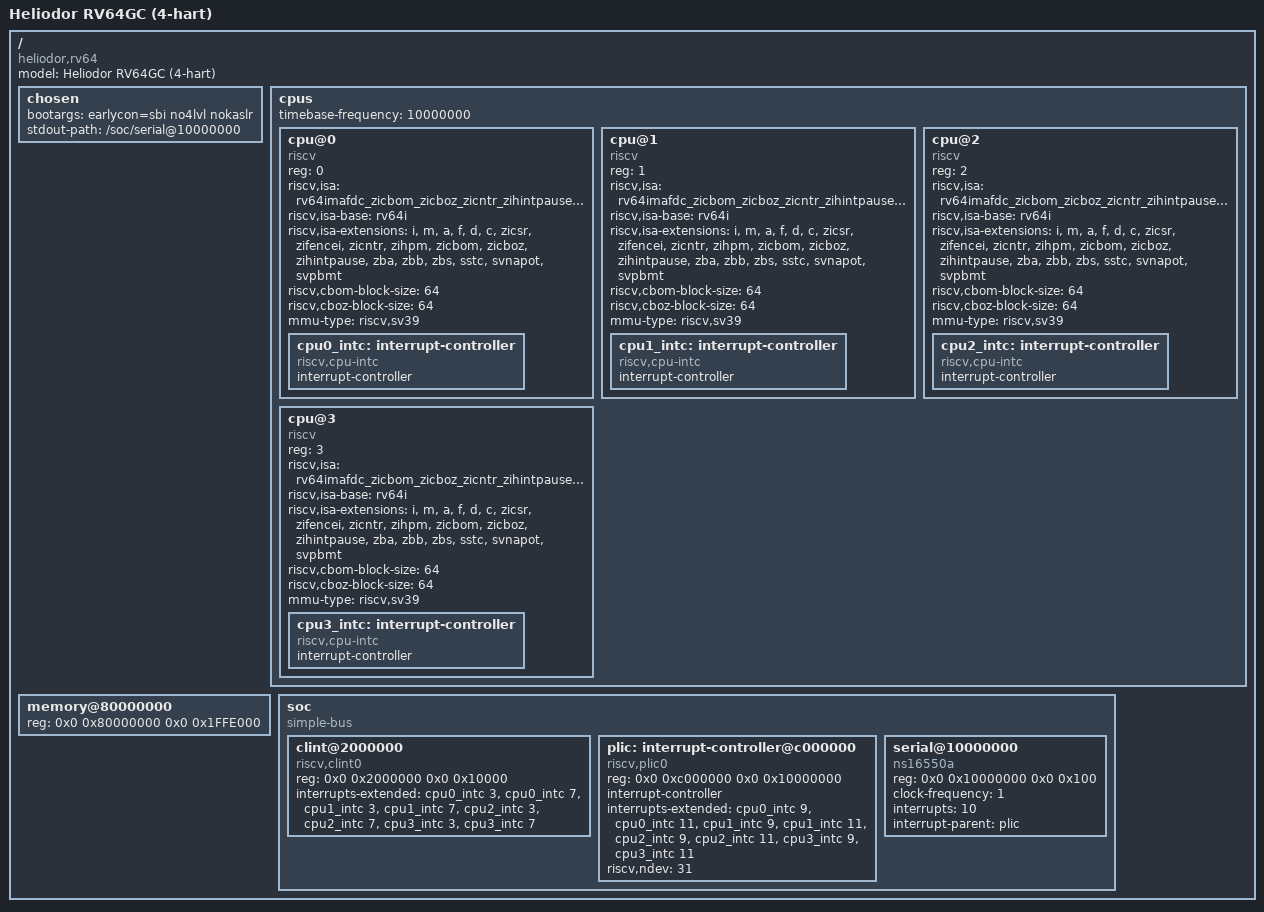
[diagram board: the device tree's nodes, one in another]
/dts-v1/;

/* Heliodor DTS for Linux 6.6 RVA23 verification (4-hart SMP).
 * Each cpu advertises the RVA23 ISA extensions via riscv,isa-extensions
 * (6.6 device-tree boot ignores the legacy riscv,isa string without
 * CONFIG_RISCV_ISA_FALLBACK). memory = 32MB - 8KB; the top 8KB is reserved
 * for the firmware HART_SCRATCH_BASE (0x81FFE000) + mscratch (0x81FFF000). */

/ {
	#address-cells = <2>;
	#size-cells = <2>;
	compatible = "heliodor,rv64";
	model = "Heliodor RV64GC (4-hart)";

	chosen {
		bootargs = "earlycon=sbi no4lvl nokaslr";
		stdout-path = "/soc/serial@10000000";
	};

	cpus {
		#address-cells = <1>;
		#size-cells = <0>;
		timebase-frequency = <10000000>;

			cpu@0 {
				device_type = "cpu";
				compatible = "riscv";
				reg = <0>;
				riscv,isa = "rv64imafdc_zicbom_zicboz_zicntr_zihintpause_zihpm_zba_zbb_zbs_sstc_svnapot_svpbmt";
				riscv,isa-base = "rv64i";
				riscv,isa-extensions = "i", "m", "a", "f", "d", "c",
				"zicsr", "zifencei", "zicntr", "zihpm",
				"zicbom", "zicboz", "zihintpause",
				"zba", "zbb", "zbs",
				"sstc", "svnapot", "svpbmt";
				riscv,cbom-block-size = <64>;
				riscv,cboz-block-size = <64>;
				mmu-type = "riscv,sv39";
				status = "okay";

				cpu0_intc: interrupt-controller {
					#interrupt-cells = <1>;
					compatible = "riscv,cpu-intc";
					interrupt-controller;
				};
			};

			cpu@1 {
				device_type = "cpu";
				compatible = "riscv";
				reg = <1>;
				riscv,isa = "rv64imafdc_zicbom_zicboz_zicntr_zihintpause_zihpm_zba_zbb_zbs_sstc_svnapot_svpbmt";
				riscv,isa-base = "rv64i";
				riscv,isa-extensions = "i", "m", "a", "f", "d", "c",
				"zicsr", "zifencei", "zicntr", "zihpm",
				"zicbom", "zicboz", "zihintpause",
				"zba", "zbb", "zbs",
				"sstc", "svnapot", "svpbmt";
				riscv,cbom-block-size = <64>;
				riscv,cboz-block-size = <64>;
				mmu-type = "riscv,sv39";
				status = "okay";

				cpu1_intc: interrupt-controller {
					#interrupt-cells = <1>;
					compatible = "riscv,cpu-intc";
					interrupt-controller;
				};
			};

			cpu@2 {
				device_type = "cpu";
				compatible = "riscv";
				reg = <2>;
				riscv,isa = "rv64imafdc_zicbom_zicboz_zicntr_zihintpause_zihpm_zba_zbb_zbs_sstc_svnapot_svpbmt";
				riscv,isa-base = "rv64i";
				riscv,isa-extensions = "i", "m", "a", "f", "d", "c",
				"zicsr", "zifencei", "zicntr", "zihpm",
				"zicbom", "zicboz", "zihintpause",
				"zba", "zbb", "zbs",
				"sstc", "svnapot", "svpbmt";
				riscv,cbom-block-size = <64>;
				riscv,cboz-block-size = <64>;
				mmu-type = "riscv,sv39";
				status = "okay";

				cpu2_intc: interrupt-controller {
					#interrupt-cells = <1>;
					compatible = "riscv,cpu-intc";
					interrupt-controller;
				};
			};

			cpu@3 {
				device_type = "cpu";
				compatible = "riscv";
				reg = <3>;
				riscv,isa = "rv64imafdc_zicbom_zicboz_zicntr_zihintpause_zihpm_zba_zbb_zbs_sstc_svnapot_svpbmt";
				riscv,isa-base = "rv64i";
				riscv,isa-extensions = "i", "m", "a", "f", "d", "c",
				"zicsr", "zifencei", "zicntr", "zihpm",
				"zicbom", "zicboz", "zihintpause",
				"zba", "zbb", "zbs",
				"sstc", "svnapot", "svpbmt";
				riscv,cbom-block-size = <64>;
				riscv,cboz-block-size = <64>;
				mmu-type = "riscv,sv39";
				status = "okay";

				cpu3_intc: interrupt-controller {
					#interrupt-cells = <1>;
					compatible = "riscv,cpu-intc";
					interrupt-controller;
				};
			};
	};

	memory@80000000 {
		device_type = "memory";
		reg = <0x0 0x80000000 0x0 0x1FFE000>;
	};

	soc {
		#address-cells = <2>;
		#size-cells = <2>;
		compatible = "simple-bus";
		ranges;

		clint@2000000 {
			compatible = "riscv,clint0";
			reg = <0x0 0x2000000 0x0 0x10000>;
			interrupts-extended = <&cpu0_intc 3>, <&cpu0_intc 7>,
			                      <&cpu1_intc 3>, <&cpu1_intc 7>,
			                      <&cpu2_intc 3>, <&cpu2_intc 7>,
			                      <&cpu3_intc 3>, <&cpu3_intc 7>;
		};

		plic: interrupt-controller@c000000 {
			compatible = "riscv,plic0";
			reg = <0x0 0xc000000 0x0 0x10000000>;
			#interrupt-cells = <1>;
			interrupt-controller;
			interrupts-extended = <&cpu0_intc 9>, <&cpu0_intc 11>,
			                      <&cpu1_intc 9>, <&cpu1_intc 11>,
			                      <&cpu2_intc 9>, <&cpu2_intc 11>,
			                      <&cpu3_intc 9>, <&cpu3_intc 11>;
			riscv,ndev = <31>;
		};

		serial@10000000 {
			compatible = "ns16550a";
			reg = <0x0 0x10000000 0x0 0x100>;
			clock-frequency = <1>;
			interrupts = <10>;
			interrupt-parent = <&plic>;
		};
	};
};
